AUTOSAR XML (schema 4-3-1)
package /TPC_Composition/Components
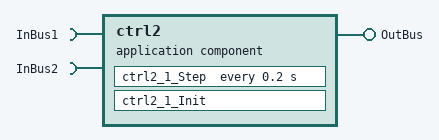
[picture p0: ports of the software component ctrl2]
  application sw component type ctrl2
    require port InBus1: nonqueued-receiver-com-spec{data-element=Value, init-value=0}, required-interface=InBus1
    require port InBus2: nonqueued-receiver-com-spec{data-element=Value, init-value=0}, required-interface=InBus2
    provide port OutBus: nonqueued-sender-com-spec{data-element=Value, init-value=0}, provided-interface=OutBus
    behavior ctrl2_1_IB: data-type-mapping=ctrl2DataTypeMappingsSet, handle-termination-and-restart=NO-SUPPORT
      timing event Event_ctrl2_1_Step: start-on-event=ctrl2_1_Step, period=0.2
      runnable ctrl2_1_Init
      runnable ctrl2_1_Step
        data-read-access:
          access IN_InBus1_Value: accessed-variable=InBus1.Value
          access IN_InBus2_Value: accessed-variable=InBus2.Value
        data-write-access:
          access OUT_OutBus_Value: accessed-variable=OutBus.Value
        parameter access SCALPRM_L_4x6_single_ar: accessed-parameter=L_4x6_single_ar, sw-calprm-axis-set=[{sw-axis-index=1, sw-axis-individual=sw-variable=InBus2.Value}, {sw-axis-index=2, sw-axis-individual=sw-variable=InBus1.Value}]
      shared-parameters:
        parameter data prototype L_4x6_single_ar: category=MAP, sw-calibration-access=READ-ONLY, type=Appl_my2d_LkupTbl, init-value=constant-reference={short-label=L_4x6_single_ar, constant=L_4x6_single_ar}
